VERSION ""

NS_ :

BS_:

BU_: TEST_NODE Pedalbox HUB_FL

BO_ 2483028044 test_msg: 2 TEST_NODE
 SG_ test_sig : 0|16@1+ (1,0) [0|0] "" Vector__XXX

BO_ 2483028619 throttle_brake: 4 Pedalbox
 SG_ raw_brake : 16|16@1+ (1,0) [0|0] "" Vector__XXX
 SG_ raw_throttle : 0|16@1+ (1,0) [0|0] "" Vector__XXX

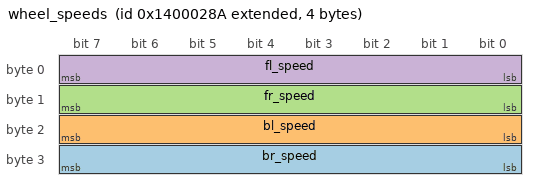
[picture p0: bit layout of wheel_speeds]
BO_ 2483028618 wheel_speeds: 4 HUB_FL
 SG_ br_speed : 24|8@1+ (1,0) [0|0] "" Vector__XXX
 SG_ bl_speed : 16|8@1+ (1,0) [0|0] "" Vector__XXX
 SG_ fr_speed : 8|8@1+ (1,0) [0|0] "" Vector__XXX
 SG_ fl_speed : 0|8@1+ (1,0) [0|0] "" Vector__XXX

BO_ 2214592650 motor_current: 1 HUB_FL
 SG_ current : 0|8@1+ (1,0) [0|0] "" Vector__XXX

CM_ BO_ 2483028044 "test_msg desc";
CM_ BO_ 2483028619 "throttle_brake desc";
CM_ BO_ 2483028618 "wheel_speeds desc";
CM_ BO_ 2214592650 "current of motor";
